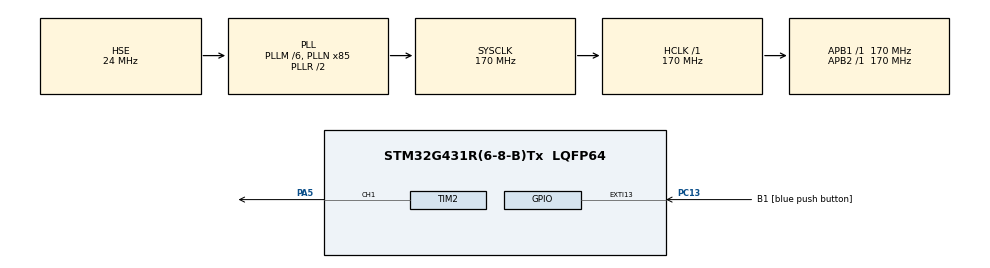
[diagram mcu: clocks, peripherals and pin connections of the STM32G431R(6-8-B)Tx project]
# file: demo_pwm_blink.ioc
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FREERTOS.Tasks01=defaultTask,24,128,StartDefaultTask,Default,NULL,Dynamic,NULL,NULL
FREERTOS.configUSE_NEWLIB_REENTRANT=1
Mcu.Family=STM32G4
Mcu.Name=STM32G431R(6-8-B)Tx
Mcu.Package=LQFP64
NVIC.PriorityGroup=NVIC_PRIORITYGROUP_4
NVIC.TIM6_DAC_IRQn=true\:15\:0\:false\:false\:true\:false\:false\:true
NVIC.TimeBase=TIM6_DAC_IRQn
NVIC.TimeBaseIP=TIM6
PA13.GPIO_Label=T_SWDIO
PA13.Signal=SYS_JTMS-SWDIO
PA14.GPIO_Label=T_SWCLK
PA14.Signal=SYS_JTCK-SWCLK
PA2.GPIO_Label=LPUART1_TX [STLINKV3E_VCP_RX]
PA2.Signal=LPUART1_TX
PA3.GPIO_Label=LPUART1_RX [STLINKV3E_VCP_TX]
PA3.Signal=LPUART1_RX
PA5.Signal=S_TIM2_CH1
PB3.GPIO_Label=T_SWO
PB3.Signal=SYS_JTDO-SWO
PC13.GPIO_Label=B1 [blue push button]
PC13.Signal=GPXTI13
PC14-OSC32_IN.Mode=LSE-External-Oscillator
PC14-OSC32_IN.Signal=RCC_OSC32_IN
PC15-OSC32_OUT.Mode=LSE-External-Oscillator
PC15-OSC32_OUT.Signal=RCC_OSC32_OUT
PF0-OSC_IN.Mode=HSE-External-Oscillator
PF0-OSC_IN.Signal=RCC_OSC_IN
PF1-OSC_OUT.Mode=HSE-External-Oscillator
PF1-OSC_OUT.Signal=RCC_OSC_OUT
ProjectManager.HeapSize=0x200
ProjectManager.StackSize=0x400
ProjectManager.TargetToolchain=STM32CubeIDE
RCC.ADC12Freq_Value=170000000
RCC.AHBFreq_Value=170000000
RCC.APB1Freq_Value=170000000
RCC.APB1TimFreq_Value=170000000
RCC.APB2Freq_Value=170000000
RCC.APB2TimFreq_Value=170000000
RCC.CortexFreq_Value=170000000
RCC.EXTERNAL_CLOCK_VALUE=12288000
RCC.HCLKFreq_Value=170000000
RCC.HSE_VALUE=24000000
RCC.HSI48_VALUE=48000000
RCC.HSI_VALUE=16000000
RCC.PLLM=RCC_PLLM_DIV6
RCC.PLLN=85
RCC.PLLSourceVirtual=RCC_PLLSOURCE_HSE
RCC.RTCClockSelection=RCC_RTCCLKSOURCE_LSE
RCC.SYSCLKFreq_VALUE=170000000
RCC.SYSCLKSource=RCC_SYSCLKSOURCE_PLLCLK
RCC.USBFreq_Value=170000000
RCC.VCOOutputFreq_Value=340000000
SH.S_TIM2_CH1.0=TIM2_CH1,PWM Generation1 CH1
TIM2.AutoReloadPreload=TIM_AUTORELOAD_PRELOAD_DISABLE
TIM2.Channel-PWM\ Generation1\ CH1=TIM_CHANNEL_1
TIM2.OCFastMode_PWM-PWM\ Generation1\ CH1=TIM_OCFAST_ENABLE
TIM2.PeriodNoDither=100
TIM2.Prescaler=68
TIM2.PulseNoDither_1=100
VP_FREERTOS_VS_CMSIS_V2.Mode=CMSIS_V2
VP_SYS_VS_DBSignals.Mode=DisableDeadBatterySignals
VP_SYS_VS_tim6.Mode=TIM6
VP_TIM2_VS_ClockSourceINT.Mode=Internal
board=NUCLEO-G431RB

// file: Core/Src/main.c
/* USER CODE BEGIN Header */
/**
  ******************************************************************************
  * @file           : main.c
  * @brief          : Main program body
  ******************************************************************************
  * @attention
  *
  * Copyright (c) 2021 STMicroelectronics.
  * All rights reserved.
  *
  * This software is licensed under terms that can be found in the LICENSE file
  * in the root directory of this software component.
  * If no LICENSE file comes with this software, it is provided AS-IS.
  *
  ******************************************************************************
  */
/* USER CODE END Header */
#include "main.h"
#include "cmsis_os.h"

TIM_HandleTypeDef htim2;

/* Definitions for defaultTask */
osThreadId_t defaultTaskHandle;
const osThreadAttr_t defaultTask_attributes = {
  .name = "defaultTask",
  .priority = (osPriority_t) osPriorityNormal,
  .stack_size = 128 * 4
};

void SystemClock_Config(void);
static void MX_GPIO_Init(void);
static void MX_TIM2_Init(void);
void StartDefaultTask(void *argument);

/* USER CODE BEGIN PFP */
uint8_t pwm_plus_value = 50;
uint8_t pwm_dir = 0; // 0 for UP, 1 for Down

/* USER CODE END PFP */

int main(void)
{

  /* MCU Configuration--------------------------------------------------------*/

  /* Reset of all peripherals, Initializes the Flash interface and the Systick. */
  HAL_Init();

  /* Configure the system clock */
  SystemClock_Config();

  /* Initialize all configured peripherals */
  MX_GPIO_Init();
  MX_TIM2_Init();
  /* USER CODE BEGIN 2 */
  HAL_TIM_PWM_Start(&htim2,TIM_CHANNEL_1);

  /* USER CODE END 2 */

  /* Init scheduler */
  osKernelInitialize();

  /* Create the thread(s) */
  /* creation of defaultTask */
  defaultTaskHandle = osThreadNew(StartDefaultTask, NULL, &defaultTask_attributes);

  /* Start scheduler */
  osKernelStart();

  /* We should never get here as control is now taken by the scheduler */
  /* Infinite loop */
  while (1)
  {

  }
}

void SystemClock_Config(void)
{
  RCC_OscInitTypeDef RCC_OscInitStruct = {0};
  RCC_ClkInitTypeDef RCC_ClkInitStruct = {0};

  /** Configure the main internal regulator output voltage
  */
  HAL_PWREx_ControlVoltageScaling(PWR_REGULATOR_VOLTAGE_SCALE1_BOOST);
  /** Initializes the RCC Oscillators according to the specified parameters
  * in the RCC_OscInitTypeDef structure.
  */
  RCC_OscInitStruct.OscillatorType = RCC_OSCILLATORTYPE_HSE;
  RCC_OscInitStruct.HSEState = RCC_HSE_ON;
  RCC_OscInitStruct.PLL.PLLState = RCC_PLL_ON;
  RCC_OscInitStruct.PLL.PLLSource = RCC_PLLSOURCE_HSE;
  RCC_OscInitStruct.PLL.PLLM = RCC_PLLM_DIV6;
  RCC_OscInitStruct.PLL.PLLN = 85;
  RCC_OscInitStruct.PLL.PLLP = RCC_PLLP_DIV2;
  RCC_OscInitStruct.PLL.PLLQ = RCC_PLLQ_DIV2;
  RCC_OscInitStruct.PLL.PLLR = RCC_PLLR_DIV2;
  if (HAL_RCC_OscConfig(&RCC_OscInitStruct) != HAL_OK)
  {
    Error_Handler();
  }
  /** Initializes the CPU, AHB and APB buses clocks
  */
  RCC_ClkInitStruct.ClockType = RCC_CLOCKTYPE_HCLK|RCC_CLOCKTYPE_SYSCLK
                              |RCC_CLOCKTYPE_PCLK1|RCC_CLOCKTYPE_PCLK2;
  RCC_ClkInitStruct.SYSCLKSource = RCC_SYSCLKSOURCE_PLLCLK;
  RCC_ClkInitStruct.AHBCLKDivider = RCC_SYSCLK_DIV1;
  RCC_ClkInitStruct.APB1CLKDivider = RCC_HCLK_DIV1;
  RCC_ClkInitStruct.APB2CLKDivider = RCC_HCLK_DIV1;

  if (HAL_RCC_ClockConfig(&RCC_ClkInitStruct, FLASH_LATENCY_4) != HAL_OK)
  {
    Error_Handler();
  }
}

static void MX_TIM2_Init(void)
{

  TIM_ClockConfigTypeDef sClockSourceConfig = {0};
  TIM_MasterConfigTypeDef sMasterConfig = {0};
  TIM_OC_InitTypeDef sConfigOC = {0};

  htim2.Instance = TIM2;
  htim2.Init.Prescaler = 68;
  htim2.Init.CounterMode = TIM_COUNTERMODE_UP;
  htim2.Init.Period = 100;
  htim2.Init.ClockDivision = TIM_CLOCKDIVISION_DIV1;
  htim2.Init.AutoReloadPreload = TIM_AUTORELOAD_PRELOAD_DISABLE;
  if (HAL_TIM_Base_Init(&htim2) != HAL_OK)
  {
    Error_Handler();
  }
  sClockSourceConfig.ClockSource = TIM_CLOCKSOURCE_INTERNAL;
  if (HAL_TIM_ConfigClockSource(&htim2, &sClockSourceConfig) != HAL_OK)
  {
    Error_Handler();
  }
  if (HAL_TIM_PWM_Init(&htim2) != HAL_OK)
  {
    Error_Handler();
  }
  sMasterConfig.MasterOutputTrigger = TIM_TRGO_RESET;
  sMasterConfig.MasterSlaveMode = TIM_MASTERSLAVEMODE_DISABLE;
  if (HAL_TIMEx_MasterConfigSynchronization(&htim2, &sMasterConfig) != HAL_OK)
  {
    Error_Handler();
  }
  sConfigOC.OCMode = TIM_OCMODE_PWM1;
  sConfigOC.Pulse = 100;
  sConfigOC.OCPolarity = TIM_OCPOLARITY_HIGH;
  sConfigOC.OCFastMode = TIM_OCFAST_ENABLE;
  if (HAL_TIM_PWM_ConfigChannel(&htim2, &sConfigOC, TIM_CHANNEL_1) != HAL_OK)
  {
    Error_Handler();
  }
  HAL_TIM_MspPostInit(&htim2);

}

static void MX_GPIO_Init(void)
{
  GPIO_InitTypeDef GPIO_InitStruct = {0};

  /* GPIO Ports Clock Enable */
  __HAL_RCC_GPIOC_CLK_ENABLE();
  __HAL_RCC_GPIOF_CLK_ENABLE();
  __HAL_RCC_GPIOA_CLK_ENABLE();
  __HAL_RCC_GPIOB_CLK_ENABLE();

  /*Configure GPIO pin : B1_Pin */
  GPIO_InitStruct.Pin = B1_Pin;
  GPIO_InitStruct.Mode = GPIO_MODE_IT_RISING;
  GPIO_InitStruct.Pull = GPIO_NOPULL;
  HAL_GPIO_Init(B1_GPIO_Port, &GPIO_InitStruct);

  /*Configure GPIO pins : LPUART1_TX_Pin LPUART1_RX_Pin */
  GPIO_InitStruct.Pin = LPUART1_TX_Pin|LPUART1_RX_Pin;
  GPIO_InitStruct.Mode = GPIO_MODE_AF_PP;
  GPIO_InitStruct.Pull = GPIO_NOPULL;
  GPIO_InitStruct.Speed = GPIO_SPEED_FREQ_LOW;
  GPIO_InitStruct.Alternate = GPIO_AF12_LPUART1;
  HAL_GPIO_Init(GPIOA, &GPIO_InitStruct);

}

/* USER CODE BEGIN 4 */
void update_pwm_value()
{
  if (pwm_dir == 0){
    pwm_plus_value++;
  }else{
    pwm_plus_value--;
  }
  if (pwm_plus_value >= 100){
    pwm_dir = 1;
  }else if (pwm_plus_value <= 0){
    pwm_dir =0;
  }
  htim2.Instance->CCR1 = (htim2.Init.Period*pwm_plus_value)/100u;

}
/* USER CODE END 4 */

void StartDefaultTask(void *argument)
{
  /* USER CODE BEGIN 5 */
  /* Infinite loop */
  for(;;)
  {
    update_pwm_value();
//    HAL_GPIO_TogglePin(GPIOA,GPIO_PIN_5);
    osDelay(5);
  }
  /* USER CODE END 5 */
}

void HAL_TIM_PeriodElapsedCallback(TIM_HandleTypeDef *htim)
{
  if (htim->Instance == TIM6) {
    HAL_IncTick();
  }
}

void Error_Handler(void)
{
  __disable_irq();
  while (1)
  {
  }
}
